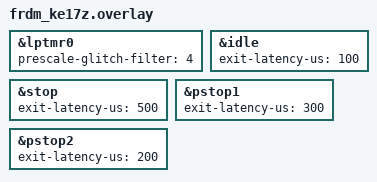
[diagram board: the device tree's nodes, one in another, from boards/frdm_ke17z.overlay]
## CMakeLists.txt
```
# Copyright 2026 NXP
#
# SPDX-License-Identifier: Apache-2.0

cmake_minimum_required(VERSION 3.28.0)
find_package(Zephyr REQUIRED HINTS $ENV{ZEPHYR_BASE})
project(pm_test)

if(TEST_S2RAM)
  target_sources(app PRIVATE
    src/s2ram.c
    boards/mcxw7x.c
  )
  target_include_directories(app PRIVATE src)
  target_link_options(app PUBLIC "LINKER:--wrap=arch_pm_s2ram_suspend")
else()
  target_sources(app PRIVATE
    src/main.c
    src/power_mgmt.c
  )
endif()
```

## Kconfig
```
# Copyright (c) 2020 Intel Corporation.
# SPDX-License-Identifier: Apache-2.0

config SUBSYS_POWER_TEST
	bool
	default y
	help
	  Hidden option enabling LPS_0 power state regardless of hardware
	  support. This ensures that power management hooks used in this
	  test.

# Include Zephyr's Kconfig.
source "Kconfig"
```

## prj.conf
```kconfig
CONFIG_LOG=y
CONFIG_ZTEST=y
CONFIG_PM=y
CONFIG_THREAD_NAME=y
CONFIG_STATS=y
CONFIG_PM_STATS=y
CONFIG_IDLE_STACK_SIZE=640
```

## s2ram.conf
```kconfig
# SPDX-FileCopyrightText: Copyright 2026 NXP
# SPDX-License-Identifier: Apache-2.0

CONFIG_PM_DEVICE=y
CONFIG_PM_POLICY_CUSTOM=y
CONFIG_UART_USE_RUNTIME_CONFIGURE=y
CONFIG_TICKLESS_KERNEL=y
CONFIG_CRC_HW_HANDLER=n
CONFIG_ARM_MPU=y
CONFIG_HW_STACK_PROTECTION=y
CONFIG_SOC_SERIES_MCXW7XX_SHUTDOWN_UNUSED_RAM=y
CONFIG_IDLE_STACK_SIZE=4096
CONFIG_MAIN_STACK_SIZE=2048
CONFIG_HEAP_MEM_POOL_SIZE=1024
CONFIG_LOG_MODE_IMMEDIATE=y
```

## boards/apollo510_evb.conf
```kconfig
CONFIG_PM_DEVICE_SYSTEM_MANAGED=y

CONFIG_SYS_CLOCK_HW_CYCLES_PER_SEC=900
CONFIG_SYS_CLOCK_TICKS_PER_SEC=28

CONFIG_SYS_HEAP_AUTO=n
CONFIG_COMMON_LIBC_MALLOC=n
CONFIG_COREMARK=y
```

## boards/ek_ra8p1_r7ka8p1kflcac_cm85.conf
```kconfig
# Copyright (c) 2025 Renesas Electronics Corporation
# SPDX-License-Identifier: Apache-2.0

CONFIG_PM_STATS=n
```

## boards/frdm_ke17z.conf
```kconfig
# Copyright 2025 NXP
#
# SPDX-License-Identifier: Apache-2.0

# Keep LPTMR as wake/idle timer via counter API
CONFIG_COUNTER=y
CONFIG_COUNTER_MCUX_LPTMR_ALARM=y
CONFIG_PM_PREWAKEUP_CONV_MODE_CEIL=y
CONFIG_SYSTEM_TIMER_RESET_BY_LPM=y
```

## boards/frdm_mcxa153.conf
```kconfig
# Copyright 2025 NXP
#
# SPDX-License-Identifier: Apache-2.0

CONFIG_PM_PREWAKEUP_CONV_MODE_CEIL=y
CONFIG_COUNTER=y
CONFIG_COUNTER_MCUX_LPTMR_ALARM=y
```

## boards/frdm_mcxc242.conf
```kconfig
# Copyright 2025 NXP
#
# SPDX-License-Identifier: Apache-2.0

# Keep LPTMR as wake/idle timer via counter API
CONFIG_COUNTER=y
CONFIG_COUNTER_MCUX_LPTMR=y
CONFIG_COUNTER_MCUX_LPTMR_ALARM=y
CONFIG_PM_PREWAKEUP_CONV_MODE_CEIL=y
CONFIG_CORTEX_M_SYSTICK_RESET_BY_LPM=y
```

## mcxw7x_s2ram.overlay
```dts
/*
 * SPDX-FileCopyrightText: Copyright 2026 NXP
 * SPDX-License-Identifier: Apache-2.0
 */

&powerdown {
	status = "okay";
};

&cpu0 {
	cpu-power-states = <&powerdown>;
};

/delete-node/ &stcm0;

&stcm {
	stcm0: system-memory@10000 {
		compatible = "mmio-sram";
		reg = <0x10000 DT_SIZE_K(32)>;
	};
};
```

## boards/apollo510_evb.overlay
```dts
/*
 * Copyright (c) 2025 Ambiq Micro Inc. <www.ambiq.com>
 *
 * SPDX-License-Identifier: Apache-2.0
 */

/ {
	chosen {
		zephyr,sram = &dtcm;
	};

	/delete-node/ sram0;
	/delete-node/ sram_no_cache;
};

&stimer0 {
	clk-source = <6>;
};
```

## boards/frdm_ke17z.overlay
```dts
/*
 * Copyright 2025 NXP
 *
 * SPDX-License-Identifier: Apache-2.0
 */

&lptmr0 {
	/delete-property/ prescale-glitch-filter-bypass;
	prescale-glitch-filter = <4>;
	status = "okay";
};

&idle {
	exit-latency-us = <100>;
};

&stop {
	exit-latency-us = <500>;
};

&pstop1 {
	exit-latency-us = <300>;
};

&pstop2 {
	exit-latency-us = <200>;
};
```

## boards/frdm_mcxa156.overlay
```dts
/*
 * Copyright 2025 NXP
 *
 * SPDX-License-Identifier: Apache-2.0
 */

&ostimer0 {
	status = "disabled";
};

&systick {
	status = "okay";
};

&lptmr0 {
	clock-frequency = <16384>;
	timer-mode-sel = <0>;
	status = "okay";
};
```

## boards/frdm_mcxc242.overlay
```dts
/*
 * Copyright 2026 NXP
 *
 * SPDX-License-Identifier: Apache-2.0
 */

&lptmr0 {
	/delete-property/ prescale-glitch-filter-bypass;
	prescale-glitch-filter = <4>;
	status = "okay";
};

&idle {
	exit-latency-us = <100>;
};

&stop {
	exit-latency-us = <500>;
};

&pstop1 {
	exit-latency-us = <300>;
};

&pstop2 {
	exit-latency-us = <200>;
};
```

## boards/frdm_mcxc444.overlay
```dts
/*
 * Copyright 2026 NXP
 *
 * SPDX-License-Identifier: Apache-2.0
 */

#include <zephyr/dt-bindings/wuc/wuc_nxp_llwu.h>

/ {
	chosen {
		zephyr,system-timer = &lptmr0;
	};
};

&lptmr0 {
	clock-frequency = <32768>;
	/delete-property/ prescale-glitch-filter;
	prescale-glitch-filter-bypass;
	clk-source = <2>;
	wakeup-ctrls = <&llwu NXP_LLWU_MODULE_WAKEUP(0)>;
};

&llwu {
	status = "okay";
};
```

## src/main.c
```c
/*
 * Copyright (c) 2020 Intel Corporation
 *
 * SPDX-License-Identifier: Apache-2.0
 */

#define LOG_LEVEL LOG_LEVEL_INF
#include <zephyr/logging/log.h>
#include <zephyr/kernel.h>
#include <zephyr/ztest.h>
#include <zephyr/tc_util.h>
LOG_MODULE_DECLARE(brd_pm_test);
#include "power_mgmt.h"

#define MAX_CYCLES 2ul

ZTEST(power_mgmt, test_pm_dummyinit)
{
	test_dummy_init();
}

ZTEST(power_mgmt, test_pm_singlethread)
{
	test_pwr_mgmt_singlethread(MAX_CYCLES);
}

ZTEST(power_mgmt, test_pm_multithread)
{
	test_pwr_mgmt_multithread(MAX_CYCLES);
}

ZTEST_SUITE(power_mgmt, NULL, NULL, NULL, NULL, NULL);
```

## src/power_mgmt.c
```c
/*
 * Copyright (c) 2020 Intel Corporation
 *
 * SPDX-License-Identifier: Apache-2.0
 */

#include <zephyr/kernel.h>
#include <zephyr/ztest.h>
#include <zephyr/pm/pm.h>
#include <zephyr/logging/log.h>
#define LOG_LEVEL LOG_LEVEL_DBG
LOG_MODULE_REGISTER(pwrmgmt_test);

/* Thread properties */
#undef TASK_STACK_SIZE
#define TASK_STACK_SIZE           1024ul
#define PRIORITY                  K_PRIO_COOP(5)

/* Sleep time should be lower than SUSPEND_TO_IDLE */
#define THREAD_A_SLEEP_TIME       100ul
#define THREAD_B_SLEEP_TIME       1000ul

/* Maximum latency should be less than 500 ms */
#define MAX_EXPECTED_MS_LATENCY   500ul

/* Sleep some extra time than minimum residency:
 * - for light it should be very little so that we get only into light sleep
 *   and not accidentally into a deep sleep.
 * - for deep sleep it can be very long as we want to ensure that we enter
 *   the deepest sleep state possible.
 */
#define LT_EXTRA_SLP_TIME_US      50ul
#define DP_EXTRA_SLP_TIME_US      1100000ul

#define SEC_TO_MSEC               1000ul

K_THREAD_STACK_DEFINE(stack_a, TASK_STACK_SIZE);
K_THREAD_STACK_DEFINE(stack_b, TASK_STACK_SIZE);

static struct k_thread thread_a_id;
static struct k_thread thread_b_id;

struct pm_counter {
	uint8_t entry_cnt;
	uint8_t exit_cnt;
};

/* Track time elapsed */
static int64_t trigger_time;
static bool checks_enabled;
static bool measure_entry_latency;
/* Track entry/exit to sleep */
struct pm_counter pm_counters[PM_STATE_COUNT];

static const struct pm_state_info residency_info[] =
	PM_STATE_INFO_LIST_FROM_DT_CPU(DT_NODELABEL(cpu0));
static size_t residency_info_len = DT_NUM_CPU_POWER_STATES(DT_NODELABEL(cpu0));

BUILD_ASSERT(DT_NUM_CPU_POWER_STATES(DT_NODELABEL(cpu0)) > 0, "No CPU power states defined");

static void pm_latency_check(void)
{
	int64_t latency;
	int secs;
	int msecs;

	latency = k_uptime_get() - trigger_time;
	secs = (int)(latency / SEC_TO_MSEC);
	msecs = (int)(latency % SEC_TO_MSEC);

	zassert_false(secs > 0 || msecs > MAX_EXPECTED_MS_LATENCY,
			"Sleep entry latency is too high: %d.%03d s.",
			secs, msecs);
}

static void notify_pm_state_entry(enum pm_state state)
{
	if (!checks_enabled) {
		return;
	}

	pm_counters[(int)state].entry_cnt++;

	if (measure_entry_latency) {
		pm_latency_check();
		/* After first PM entry disable further checks since there can
		 * be multiple PM entry-exit events e.g. due to spurious
		 * wakeup
		 */
		measure_entry_latency = false;
	}
}

static void notify_pm_state_exit(enum pm_state state)
{
	if (!checks_enabled) {
		return;
	}

	pm_counters[(int)state].exit_cnt++;
}

static struct pm_notifier notifier = {
	.state_entry = notify_pm_state_entry,
	.state_exit = notify_pm_state_exit,
};

static void pm_check_counters(uint8_t cycles)
{
	for (int i = 0; i < PM_STATE_COUNT; i++) {

		LOG_INF("PM state[%d] entry counter %d\n", i,
			pm_counters[i].entry_cnt);
		LOG_INF("PM state[%d] exit counter %d\n", i,
			pm_counters[i].exit_cnt);

		zassert_equal(pm_counters[i].entry_cnt,
				pm_counters[i].exit_cnt,
				"PM counters entry/exit mismatch");

		pm_counters[i].entry_cnt = 0;
		pm_counters[i].exit_cnt = 0;
	}
}

static void pm_reset_counters(void)
{
	for (int i = 0; i < PM_STATE_COUNT; i++) {
		pm_counters[i].entry_cnt = 0;
		pm_counters[i].exit_cnt = 0;
	}

	checks_enabled = false;
	measure_entry_latency = false;
}

static void pm_trigger_marker(void)
{
	trigger_time = k_uptime_get();

	printk("PM >\n");
}

static void pm_exit_marker(void)
{
	int64_t residency_delta;
	int secs;
	int msecs;

	printk("PM <\n");

	if (trigger_time > 0) {
		residency_delta = k_uptime_get() - trigger_time;
		secs = (int)(residency_delta / SEC_TO_MSEC);
		msecs = (int)(residency_delta % SEC_TO_MSEC);
		LOG_INF("PM sleep residency %d.%03d seconds", secs, msecs);
	}
}

static int task_a_init(void)
{
	LOG_INF("Thread task A init");

	return 0;
}

static int task_b_init(void)
{
	LOG_INF("Thread task B init");

	return 0;
}

void task_a_thread(void *p1, void *p2, void *p3)
{
	while (true) {
		k_msleep(THREAD_A_SLEEP_TIME);
		printk("A");
	}
}

static void task_b_thread(void *p1, void *p2, void *p3)
{
	while (true) {
		k_msleep(THREAD_B_SLEEP_TIME);
		printk("B");
	}
}

static void create_tasks(void)
{
	task_a_init();
	task_b_init();

	k_thread_create(&thread_a_id, stack_a, TASK_STACK_SIZE, task_a_thread,
		NULL, NULL, NULL, PRIORITY,  K_INHERIT_PERMS, K_FOREVER);
	k_thread_create(&thread_b_id, stack_b, TASK_STACK_SIZE, task_b_thread,
		NULL, NULL, NULL, PRIORITY,  K_INHERIT_PERMS, K_FOREVER);

	k_thread_start(&thread_a_id);
	k_thread_start(&thread_b_id);

}

static void destroy_tasks(void)
{
	k_thread_abort(&thread_a_id);
	k_thread_abort(&thread_b_id);

	k_thread_join(&thread_a_id, K_FOREVER);
	k_thread_join(&thread_b_id, K_FOREVER);
}

static void suspend_all_tasks(void)
{
	k_thread_suspend(&thread_a_id);
	k_thread_suspend(&thread_b_id);
}

static void resume_all_tasks(void)
{
	k_thread_resume(&thread_a_id);
	k_thread_resume(&thread_b_id);
}

int test_pwr_mgmt_multithread(uint8_t cycles)
{
	uint8_t iterations = cycles;

	pm_notifier_register(&notifier);
	create_tasks();

	LOG_INF("PM multi-thread test started for cycles: %d", cycles);

	checks_enabled = true;
	while (iterations-- > 0) {

		/* Light sleep cycle */
		LOG_INF("Suspend...");
		suspend_all_tasks();
		LOG_INF("About to enter light sleep");
		measure_entry_latency = true;
		pm_trigger_marker();
		k_usleep(residency_info[0].min_residency_us +
				LT_EXTRA_SLP_TIME_US);

		LOG_INF("Wake from Light Sleep");
		pm_exit_marker();
		LOG_INF("Resume");
		resume_all_tasks();

		/* Deep sleep cycle */
		/* Platforms that do not automatically enter deep sleep */
		/* states in its residency policy will simply enter light */
		/* sleep states instead */
		LOG_INF("Suspend...");
		suspend_all_tasks();
		LOG_INF("About to enter deep sleep");

		measure_entry_latency = true;
		pm_trigger_marker();
		k_usleep(
			residency_info[residency_info_len - 1].min_residency_us +
			DP_EXTRA_SLP_TIME_US);

		LOG_INF("Wake from Deep Sleep");
		pm_exit_marker();
		LOG_INF("Resume");
		resume_all_tasks();
	}

	destroy_tasks();
	pm_notifier_unregister(&notifier);

	LOG_INF("PM multi-thread completed");
	pm_check_counters(cycles);
	pm_reset_counters();

	return 0;
}

int test_pwr_mgmt_singlethread(uint8_t cycles)
{
	uint8_t iterations = cycles;

	LOG_INF("PM single-thread test started for cycles: %d", cycles);

	pm_notifier_register(&notifier);
	checks_enabled = true;
	while (iterations-- > 0) {

		/* Trigger Light Sleep 1 state. 48MHz PLL stays on */
		LOG_INF("About to enter light sleep");
		measure_entry_latency = true;
		pm_trigger_marker();
		k_usleep(residency_info[0].min_residency_us +
				LT_EXTRA_SLP_TIME_US);
		LOG_INF("Wake from Light Sleep");
		pm_exit_marker();

		/* Trigger Deep Sleep 1 state. 48MHz PLL off */
		/* Platforms that do not automatically enter deep sleep */
		/* states in its residency policy will simply enter light */
		/* sleep states instead */
		LOG_INF("About to enter deep Sleep");
		measure_entry_latency = true;
		pm_trigger_marker();
		k_usleep(
			residency_info[residency_info_len - 1].min_residency_us +
			DP_EXTRA_SLP_TIME_US);
		LOG_INF("Wake from Deep Sleep");
		pm_exit_marker();
	}

	pm_notifier_unregister(&notifier);
	LOG_INF("PM single-thread completed");
	pm_check_counters(cycles);
	pm_reset_counters();

	return 0;
}

int test_dummy_init(void)
{
	uint8_t iterations = 1;

	LOG_INF("PM dummy single-thread test started for one cycle");

	checks_enabled = true;
	while (iterations-- > 0) {
		LOG_INF("About to enter light sleep");
		measure_entry_latency = true;
		pm_trigger_marker();
		k_usleep(residency_info[0].min_residency_us +
				LT_EXTRA_SLP_TIME_US);
		LOG_INF("Wake from Light Sleep");
		pm_exit_marker();

		LOG_INF("About to enter deep Sleep");
		measure_entry_latency = true;
		pm_trigger_marker();
		k_usleep(
			residency_info[residency_info_len - 1].min_residency_us +
			DP_EXTRA_SLP_TIME_US);
		LOG_INF("Wake from Deep Sleep");
		pm_exit_marker();
	}

	LOG_INF("PM dummy single-thread completed");
	pm_reset_counters();
	return 0;
}
```

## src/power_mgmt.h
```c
/*
 * Copyright (c) 2020 Intel Corporation
 * Copyright 2026 NXP
 *
 * SPDX-License-Identifier: Apache-2.0
 */

#ifndef __TEST_PWRMGMT_H__
#define __TEST_PWRMGMT_H__


/** @brief Alternates between light and deep sleep cycles.
 *
 * For light sleep, the test sleeps in main thread for 500 ms longer than
 * SUSPEND_TO_IDLE.
 *
 * Similarly for deep sleep, the test sleeps in the main thread for 500 ms
 * longer than STANDBY.
 *
 * @param cycles to repeat the cycle described above.
 * @retval 0 if successful, errno otherwise.
 */
int test_pwr_mgmt_singlethread(uint8_t cycles);

/** @brief Alternates between light and deep sleep cycles.
 *
 * Performs same approach to achieve light and deep sleep, but additional
 * it suspend all threads within the app.
 *
 * @param cycles to repeat the cycle described above.
 * @retval 0 if successful, errno otherwise.
 */
int test_pwr_mgmt_multithread(uint8_t cycles);

/** @brief Initializes the board simply without assertions
 *
 * Performs a dummy initialization for the board to enter light/deep sleep
 * without assertions to check if power management is enabled correctly
 * on the board. Also serves to initialize the counters.
 *
 * @retval 0 if successful, errno otherwise.
 */
int test_dummy_init(void);

void test_pm_s2ram_prepare(void);
void test_pm_s2ram_resume(void);

#endif /* __TEST_PWRMGMT_H__ */
```

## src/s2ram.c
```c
/*
 * SPDX-FileCopyrightText: Copyright 2026 NXP
 * SPDX-License-Identifier: Apache-2.0
 */

#include <errno.h>
#include <stdbool.h>
#include <zephyr/arch/common/pm_s2ram.h>
#include <zephyr/kernel.h>
#include <zephyr/pm/pm.h>
#include <zephyr/pm/policy.h>
#include <zephyr/ztest.h>
#include "power_mgmt.h"

#define CYCLES 10U
#define PATTERN 0x5a5aa5a5U
#define WORDS 16U

BUILD_ASSERT(IS_ENABLED(CONFIG_PM_S2RAM), "The scenario requires an enabled S2RAM state");

static const struct pm_state_info states[] =
	PM_STATE_INFO_LIST_FROM_DT_CPU(DT_NODELABEL(cpu0));
static volatile uint32_t data_pattern = PATTERN;
static volatile uint32_t bss_pattern;
static volatile unsigned int suspend_calls;
static volatile int suspend_result;
static unsigned int worker_rounds;
static unsigned int worker_failures;

K_SEM_DEFINE(worker_resume, 0, 1);
K_SEM_DEFINE(worker_checked, 0, 1);
K_THREAD_STACK_DEFINE(worker_stack, 1024);
static struct k_thread worker_thread;

int __real_arch_pm_s2ram_suspend(pm_s2ram_system_off_fn_t system_off);

int __wrap_arch_pm_s2ram_suspend(pm_s2ram_system_off_fn_t system_off)
{
	suspend_calls++;
	suspend_result = __real_arch_pm_s2ram_suspend(system_off);
	return suspend_result;
}

const struct pm_state_info *pm_policy_next_state(uint8_t cpu, int32_t ticks)
{
	ARG_UNUSED(cpu);
	ARG_UNUSED(ticks);

	/* Only the forced transition may suspend, including during console recovery. */
	return NULL;
}

static void retained_worker(void *p1, void *p2, void *p3)
{
	volatile uint32_t stack_pattern[WORDS];

	ARG_UNUSED(p1);
	ARG_UNUSED(p2);
	ARG_UNUSED(p3);

	for (size_t i = 0; i < WORDS; i++) {
		stack_pattern[i] = PATTERN ^ i;
	}
	k_sem_give(&worker_checked);

	while (true) {
		k_sem_take(&worker_resume, K_FOREVER);
		for (size_t i = 0; i < WORDS; i++) {
			if (stack_pattern[i] != (PATTERN ^ i)) {
				worker_failures++;
			}
		}
		worker_rounds++;
		k_sem_give(&worker_checked);
	}
}

ZTEST(power_mgmt, test_pm_multithread)
{
	const struct pm_state_info *state = NULL;
	volatile uint32_t stack_pattern[WORDS];
	uint32_t *heap = k_malloc(WORDS * sizeof(*heap));
	volatile uint32_t *heap_pattern = heap;

	zassert_not_null(heap);
	zassert_equal(data_pattern, PATTERN);
	zassert_equal(bss_pattern, 0);
	for (size_t i = 0; i < ARRAY_SIZE(states); i++) {
		if (states[i].state == PM_STATE_SUSPEND_TO_RAM) {
			state = &states[i];
			break;
		}
	}
	zassert_not_null(state, "No S2RAM state in cpu-power-states");

	k_thread_create(&worker_thread, worker_stack, K_THREAD_STACK_SIZEOF(worker_stack),
			retained_worker, NULL, NULL, NULL, K_PRIO_PREEMPT(2), 0, K_NO_WAIT);
	zassert_ok(k_sem_take(&worker_checked, K_SECONDS(1)), "Worker did not start");

	for (unsigned int cycle = 1; cycle <= CYCLES; cycle++) {
		uint32_t salt = PATTERN ^ cycle;
		unsigned int old_calls = suspend_calls;
		int64_t before;
		int64_t elapsed;

		data_pattern = salt;
		bss_pattern = ~salt;
		for (size_t i = 0; i < WORDS; i++) {
			stack_pattern[i] = salt ^ i;
			heap_pattern[i] = ~salt ^ i;
		}
		test_pm_s2ram_prepare();
		suspend_result = -EINPROGRESS;
		zassert_true(pm_state_force(0, state), "Could not force S2RAM");
		before = k_uptime_get();
		k_msleep(500);
		elapsed = k_uptime_get() - before;
		if (suspend_result == 0) {
			test_pm_s2ram_resume();
		}

		zassert_equal(suspend_calls, old_calls + 1, "Missing or repeated S2RAM entry");
		zassert_equal(suspend_result, 0, "S2RAM did not resume: %d", suspend_result);
		zassert_true(elapsed >= 500, "Sleep timeout fired early");
		zassert_equal(data_pattern, salt);
		zassert_equal(bss_pattern, ~salt);
		for (size_t i = 0; i < WORDS; i++) {
			zassert_equal(stack_pattern[i], salt ^ i, "Main stack was not retained");
			zassert_equal(heap_pattern[i], ~salt ^ i, "Heap was not retained");
		}
		k_sem_give(&worker_resume);
		zassert_ok(k_sem_take(&worker_checked, K_SECONDS(1)), "Worker did not resume");
		zassert_equal(worker_failures, 0, "Worker stack was not retained");
		zassert_equal(worker_rounds, cycle, "Worker progress was not retained");
		printk("PM S2RAM cycle %u PASS\n", cycle);
	}

	k_thread_abort(&worker_thread);
	k_free(heap);
}

ZTEST_SUITE(power_mgmt, NULL, NULL, NULL, NULL, NULL);
```
